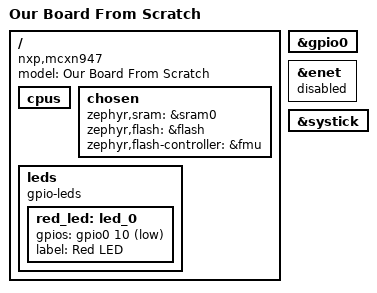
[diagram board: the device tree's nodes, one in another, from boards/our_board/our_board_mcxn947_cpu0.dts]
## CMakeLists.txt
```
cmake_minimum_required(VERSION 3.20.0)

list(APPEND BOARD_ROOT ${CMAKE_CURRENT_SOURCE_DIR})

find_package(Zephyr REQUIRED)
project(my_zephyr_app)

add_subdirectory(drivers/our_driver)

target_sources(app PRIVATE src/main.cpp)
```

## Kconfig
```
menuconfig LED_SUBSYSTEM
    bool "LED Subsystem"
    default y

if LED_SUBSYSTEM

choice BLINK_SLEEP_TIME_CHOICE
    prompt "LED blink sleep time"
    default BLINK_SLEEP_TIME_1000ms

config BLINK_SLEEP_TIME_250ms
    bool "Fast (250ms)"

config BLINK_SLEEP_TIME_500ms
    bool "Medium fast (500ms)"

config BLINK_SLEEP_TIME_1000ms
    bool "Medium slow (1s)"

config BLINK_SLEEP_TIME_2000ms
    bool "Slow (2s)"
endchoice # BLINK_SLEEP_TIME_CHOICE

config BLINK_SLEEP_TIME_MS
    int
    default 250  if BLINK_SLEEP_TIME_250ms
    default 500  if BLINK_SLEEP_TIME_500ms
    default 1000 if BLINK_SLEEP_TIME_1000ms
    default 2000 if BLINK_SLEEP_TIME_2000ms
    default 0

menuconfig ADVANCED_LED_SETTINGS
    bool "Advanced LED settings"
    default y

if ADVANCED_LED_SETTINGS

config LED_BRIGHTNESS
    int "LED brightness (0-100)"
    default 100
    range 0 100

config LED_FADE_DURATION
    int "LED fade duration (ms)"
    default 500
    range 0 5000

menu "Expert settings"
visible if ADVANCED_LED_SETTINGS

config LED_DEBUG
    bool "Enable LED debugging"
    default n

config CUSTOM_BLINK_PATTERN
    bool "Custom blink pattern"
    default n
endmenu # Expert settings

endif # ADVANCED_LED_SETTINGS
endif # LED_SUBSYSTEM

config APP_HEARBEAT_PERIOD_MS
    int "Application hearbeat period (100-2000)"
    default 500
    range 100 2000

source "Kconfig.zephyr"
rsource "drivers/our_driver/Kconfig"
```

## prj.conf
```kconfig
CONFIG_GPIO=y
CONFIG_LOG=y
CONFIG_OUR_DRIVER=y
CONFIG_SHELL=y
```

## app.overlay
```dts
/{
	aliases{
		app-led = &red_led;
	};
};

/{
	our_driver0: our_driver{
		compatible = "our,driver";
		status = "okay";
		gpios = <&gpio0 27 GPIO_ACTIVE_LOW>;
	};
};
```

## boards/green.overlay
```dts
/{
	aliases{
		warning-led = &green_led;
	};
};
```

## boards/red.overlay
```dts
/{
	aliases{
		warning-led = &red_led;
	};
};
```

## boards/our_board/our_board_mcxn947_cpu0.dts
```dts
/dts-v1/;

#include <nxp/nxp_mcxn94x.dtsi>

/ {
	model = "Our Board From Scratch";
	compatible = "nxp,mcxn947", "nxp,mcx";

	cpus {
		/delete-node/ cpu@1;
	};

	chosen {
		zephyr,sram = &sram0;
		zephyr,flash = &flash;
		zephyr,flash-controller = &fmu;
	};

	leds {
		compatible = "gpio-leds";
		red_led: led_0 {
			gpios = <&gpio0 10 GPIO_ACTIVE_LOW>;
			label = "Red LED";
		};
	};
};

&gpio0 {
	status = "okay";
};

/* Enabled by the SoC dtsi but needs pinctrl; unused on this board. */
&enet {
	status = "disabled";
};

/* System timer; SYS_CLOCK_HW_CYCLES_PER_SEC = 150MHz core clock. */
&systick {
	status = "okay";
};
```

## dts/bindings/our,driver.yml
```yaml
description: Our Simple GPIO driver 
compatible: "our,driver"
include: base.yaml
properties:
    gpios:
      type: phandle-array
      required: true
      description: Connected GPIO pin
```

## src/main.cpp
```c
#include <zephyr/drivers/gpio.h>
#include<zephyr/drivers/sensor.h>
#include <zephyr/kernel.h>
#include <zephyr/logging/log.h>
#include "our_driver.h"

/* The devicetree node identifier for the "led0" alias. */
#define LED_NODE DT_ALIAS(app_led)

static const struct gpio_dt_spec led = GPIO_DT_SPEC_GET(LED_NODE, gpios);

LOG_MODULE_REGISTER(main, LOG_LEVEL_INF);

namespace Driver::Test
{
    void ToggleLed()
    {
        const struct device* driver = DEVICE_DT_GET(DT_NODELABEL(our_driver0));
        struct sensor_value value;

        our_driver_set_enabled(driver, true);                         // switch is ON
        sensor_sample_fetch(driver);                                  // LED turns ON 
        k_msleep(1000);
        sensor_channel_get(driver, SENSOR_CHAN_AMBIENT_TEMP, &value); // LED turns OFF
        k_msleep(1000);
        our_driver_set_enabled(driver, false);                        // switch is OFF
        sensor_sample_fetch(driver);                                  // LED stays OFF (fetch is ignored)
        k_msleep(1000);
    }

} // Driver::Test

int main(void)
{
    Driver::Test::ToggleLed();

    bool led_state = true;

    if (!gpio_is_ready_dt(&led)) return 0;

    if (gpio_pin_configure_dt(&led, GPIO_OUTPUT_ACTIVE) < 0) return 0;

    while (1) {
        if (gpio_pin_toggle_dt(&led) < 0) return 0;

        led_state = !led_state;
        LOG_INF("LED state: %s", led_state ? "ON" : "OFF");
        k_msleep(CONFIG_APP_HEARBEAT_PERIOD_MS);
    }
    return 0;
}
```
